AUTOSAR XML (schema 4-3-1)
package /TPC_Composition/Components
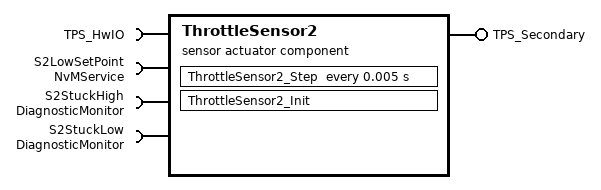
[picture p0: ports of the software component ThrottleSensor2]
  sensor actuator sw component type ThrottleSensor2
    require port TPS_HwIO: nonqueued-receiver-com-spec{data-element=Value, init-value=0}, required-interface=TPS_HwIO
    provide port TPS_Secondary: nonqueued-sender-com-spec{data-element=Value, init-value=0}, provided-interface=TPS_Secondary
    require port S2LowSetPoint: required-interface=NvMService
    require port S2StuckHigh: required-interface=DiagnosticMonitor
    require port S2StuckLow: required-interface=DiagnosticMonitor
    behavior ThrottleSensor2_IB: data-type-mapping=ThrottleSensor2DataTypeMappingsSet, handle-termination-and-restart=NO-SUPPORT
      ar-typed-per-instance-memorys:
        data autosar_tpc_throttl_LowSetPoint: category=VALUE, sw-calibration-access=READ-ONLY, type=uint8
      timing event Event_ThrottleSensor2_Step: start-on-event=ThrottleSensor2_Step, period=0.005
      runnable ThrottleSensor2_Init
        async call SC_S2LowSetPoint_ReadBlock: operation=S2LowSetPoint.ReadBlock, timeout=1
      runnable ThrottleSensor2_Step
        data-read-access:
          access IN_TPS_HwIO_Value: accessed-variable=TPS_HwIO.Value
        data-write-access:
          access OUT_TPS_Secondary_Value: accessed-variable=TPS_Secondary.Value
        parameter access SCALPRM_TPSSecondaryPercent_LkupTbl: accessed-parameter=TPSSecondaryPercent_LkupTbl
        sync call SC_S2StuckHigh_SetEventStatus: operation=S2StuckHigh.SetEventStatus, timeout=1.0E-06
        sync call SC_S2StuckLow_SetEventStatus: operation=S2StuckLow.SetEventStatus, timeout=1.0E-06
      shared-parameters:
        parameter data prototype TPSSecondaryPercent_LkupTbl: category=CURVE, sw-calibration-access=READ-WRITE, type=Appl_TPSSecondaryPercent_LkupTbl, init-value=constant-reference={short-label=TPSSecondaryPercent_LkupTbl, constant=TPSSecondaryPercent_LkupTbl}
